VERSION ""

NS_ :

BS_:

BU_:

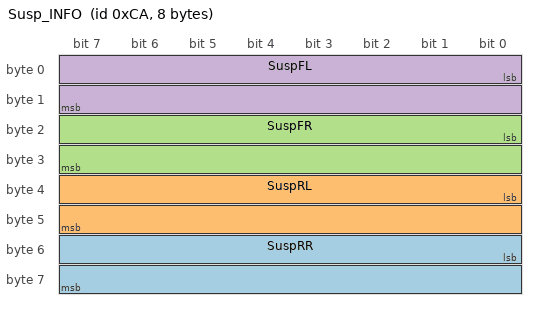
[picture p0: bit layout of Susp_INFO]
BO_ 202 Susp_INFO: 8 Vector__XXX
 SG_ SuspRR : 48|16@1- (0.01,0) [-327.68|327.67] "" Vector__XXX
 SG_ SuspRL : 32|16@1- (0.01,0) [-327.68|327.67] "" Vector__XXX
 SG_ SuspFR : 16|16@1- (0.01,0) [-327.68|327.67] "" Vector__XXX
 SG_ SuspFL : 0|16@1- (0.01,0) [-327.68|327.67] "" Vector__XXX

BA_DEF_  "BusType" STRING ;
BA_DEF_DEF_  "BusType" "CAN";
